AUTOSAR XML (schema 4-3-0)
package /ComponentTypes
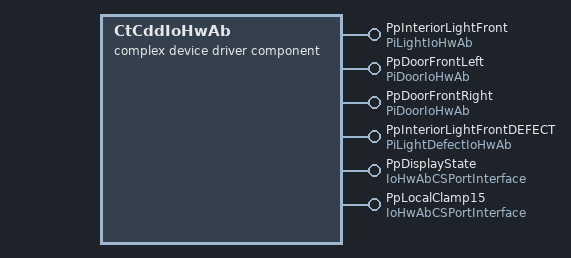
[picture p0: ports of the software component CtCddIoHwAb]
  complex device driver sw component type CtCddIoHwAb
    6 x provide port:
      PpInteriorLightFront: server-com-spec{operation=WriteChannel, queue-length=1}, provided-interface=PiLightIoHwAb
      PpDoorFrontLeft: server-com-spec{operation=ReadChannel, queue-length=1}, provided-interface=PiDoorIoHwAb
      PpDoorFrontRight: server-com-spec{operation=ReadChannel, queue-length=1}, provided-interface=PiDoorIoHwAb
      PpInteriorLightFrontDEFECT: server-com-spec{operation=ReadChannel, queue-length=1}, provided-interface=PiLightDefectIoHwAb
      PpDisplayState: provided-com-specs=[{operation=ReadChannel, queue-length=1}, {operation=WriteChannel, queue-length=1}], provided-interface=IoHwAbCSPortInterface
      PpLocalClamp15: provided-com-specs=[{operation=ReadChannel, queue-length=1}, {operation=WriteChannel, queue-length=1}], provided-interface=IoHwAbCSPortInterface
    behavior CtCddIoHwAb_InternalBehavior
      8 x operation invoked event:
        OIT_PpDoorFrontLeft_ReadChannel_PpDoorFrontLeft_ReadChannel: start-on-event=RCtCddIoHwAb_PpDoorFrontLeft_ReadChannel, operation=PpDoorFrontLeft.ReadChannel
        OIT_PpInteriorLightFront_WriteChannel_PpInteriorLightFront_WriteChannel: start-on-event=RCtCddIoHwAb_PpInteriorLightFront_WriteChannel, operation=PpInteriorLightFront.WriteChannel
        OIT_PpDoorFrontRight_ReadChannel_PpDoorFrontRight_ReadChannel: start-on-event=RCtCddIoHwAb_PpDoorFrontRight_ReadChannel, operation=PpDoorFrontRight.ReadChannel
        OIT_PpInteriorLightFrontDEFECT_ReadChannel_PpInteriorLightFrontDEFECT_ReadChannel: start-on-event=RCtCddIoHwAb_PpInteriorLightFrontDEFECT_ReadChannel, operation=PpInteriorLightFrontDEFECT.ReadChannel
        OIT_RCtCddIoHwAb_PpDisplayState_ReadChannel_PpDisplayState_ReadChannel: start-on-event=RCtCddIoHwAb_PpDisplayState_ReadChannel, operation=PpDisplayState.ReadChannel
        OIT_RCtCddIoHwAb_PpDisplayState_WriteChannel_PpDisplayState_WriteChannel: start-on-event=RCtCddIoHwAb_PpDisplayState_WriteChannel, operation=PpDisplayState.WriteChannel
        OIT_RCtCddIoHwAb_PpLocalClamp15_ReadChannel_PpLocalClamp15_ReadChannel: start-on-event=RCtCddIoHwAb_PpLocalClamp15_ReadChannel, operation=PpLocalClamp15.ReadChannel
        OIT_RCtCddIoHwAb_PpLocalClamp15_WriteChannel_PpLocalClamp15_WriteChannel: start-on-event=RCtCddIoHwAb_PpLocalClamp15_WriteChannel, operation=PpLocalClamp15.WriteChannel
      8 x runnable:
        RCtCddIoHwAb_PpDoorFrontLeft_ReadChannel
        RCtCddIoHwAb_PpInteriorLightFront_WriteChannel
        RCtCddIoHwAb_PpDoorFrontRight_ReadChannel
        RCtCddIoHwAb_PpInteriorLightFrontDEFECT_ReadChannel
        RCtCddIoHwAb_PpDisplayState_ReadChannel
        RCtCddIoHwAb_PpDisplayState_WriteChannel
        RCtCddIoHwAb_PpLocalClamp15_ReadChannel
        RCtCddIoHwAb_PpLocalClamp15_WriteChannel
  swc implementation CtCddIoHwAb_Implementation: behavior=CtCddIoHwAb_InternalBehavior
